AUTOSAR XML (schema 4-2-2)
package /Components
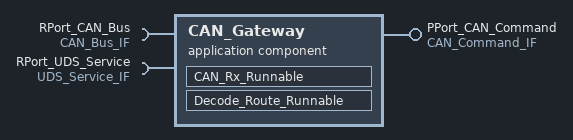
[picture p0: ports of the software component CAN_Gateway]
  application sw component type CAN_Gateway
    provide port PPort_CAN_Command: provided-interface=CAN_Command_IF
    require port RPort_CAN_Bus: required-interface=CAN_Bus_IF
    require port RPort_UDS_Service: required-interface=UDS_Service_IF
    behavior CAN_Gateway_Behavior
      asynchronous server call returns event UDS_Response_Returned_Event: start-on-event=UDS_Request_Handler, event-source=UDS_Forward_Result
      data received event CAN_Frame_Received_Event: start-on-event=UDS_Request_Handler
      runnable CAN_Rx_Runnable: symbol=CAN_Gateway_CAN_Rx_Runnable
        data-receive-point-by-values:
          access CAN_Frame_Access: accessed-variable=RPort_CAN_Bus.Raw_CAN_Frame
      runnable Decode_Route_Runnable: minimum-start-interval=10, symbol=CAN_Gateway_Decode_Route_Runnable
        data-send-points:
          access Decoded_Command_Send: accessed-variable=PPort_CAN_Command.Decoded_Command
        async call UDS_Forward_Call: operation=RPort_UDS_Service.RequestResponse, timeout=50
